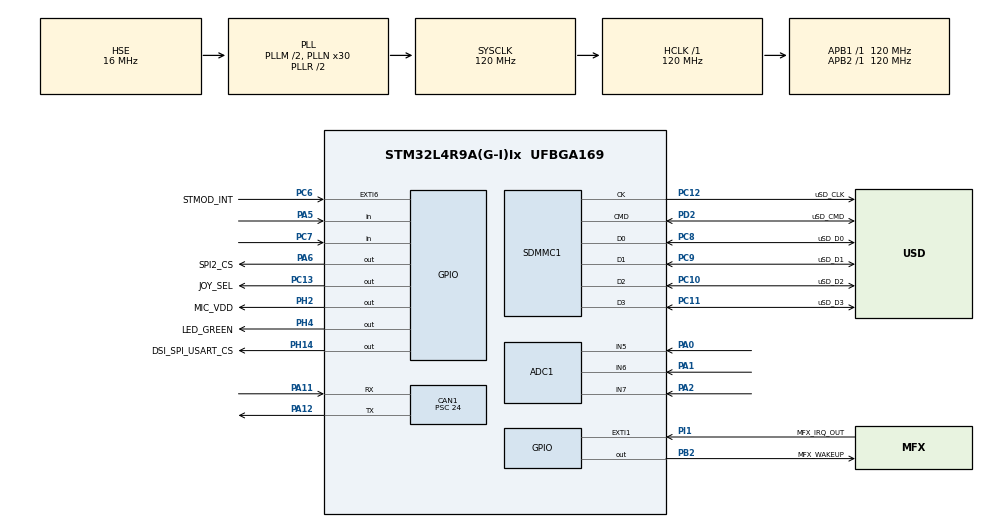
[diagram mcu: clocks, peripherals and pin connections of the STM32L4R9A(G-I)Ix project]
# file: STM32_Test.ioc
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ADC1.Channel-0\#ChannelRegularConversion=ADC_CHANNEL_5
ADC1.Channel-1\#ChannelRegularConversion=ADC_CHANNEL_6
ADC1.Channel-2\#ChannelRegularConversion=ADC_CHANNEL_7
ADC1.ClockPrescaler=ADC_CLOCK_ASYNC_DIV4
ADC1.ContinuousConvMode=ENABLE
ADC1.DMAContinuousRequests=ENABLE
ADC1.DataAlign=ADC_DATAALIGN_RIGHT
ADC1.EOCSelection=ADC_EOC_SEQ_CONV
ADC1.NbrOfConversion=3
ADC1.NbrOfConversionFlag=1
ADC1.OffsetNumber-0\#ChannelRegularConversion=ADC_OFFSET_NONE
ADC1.OffsetNumber-1\#ChannelRegularConversion=ADC_OFFSET_NONE
ADC1.OffsetNumber-2\#ChannelRegularConversion=ADC_OFFSET_NONE
ADC1.Rank-0\#ChannelRegularConversion=1
ADC1.Rank-1\#ChannelRegularConversion=2
ADC1.Rank-2\#ChannelRegularConversion=3
ADC1.SamplingTime-0\#ChannelRegularConversion=ADC_SAMPLETIME_92CYCLES_5
ADC1.SamplingTime-1\#ChannelRegularConversion=ADC_SAMPLETIME_92CYCLES_5
ADC1.SamplingTime-2\#ChannelRegularConversion=ADC_SAMPLETIME_92CYCLES_5
ADC1.master=1
CAN1.BS1=CAN_BS1_8TQ
CAN1.CalculateBaudRate=500000
CAN1.CalculateTimeBit=2000
CAN1.CalculateTimeQuantum=200.0
CAN1.Prescaler=24
DSIHOST_CKN.GPIO_Label=DSI_CK_N
DSIHOST_CKN.Signal=DSIHOST_CKN
DSIHOST_CKP.GPIO_Label=DSI_CK_P
DSIHOST_CKP.Signal=DSIHOST_CKP
DSIHOST_D0N.GPIO_Label=DSI_D0_N
DSIHOST_D0N.Signal=DSIHOST_D0N
DSIHOST_D0P.GPIO_Label=DSI_D0_P
DSIHOST_D0P.Signal=DSIHOST_D0P
DSIHOST_D1N.GPIO_Label=DSI_D1_N
DSIHOST_D1N.Signal=DSIHOST_D1N
DSIHOST_D1P.GPIO_Label=DSI_D1_P
DSIHOST_D1P.Signal=DSIHOST_D1P
Dma.ADC1.0.Direction=DMA_PERIPH_TO_MEMORY
Dma.ADC1.0.EventEnable=DISABLE
Dma.ADC1.0.Instance=DMA1_Channel4
Dma.ADC1.0.MemDataAlignment=DMA_MDATAALIGN_HALFWORD
Dma.ADC1.0.MemInc=DMA_MINC_ENABLE
Dma.ADC1.0.Mode=DMA_CIRCULAR
Dma.ADC1.0.PeriphDataAlignment=DMA_PDATAALIGN_HALFWORD
Dma.ADC1.0.PeriphInc=DMA_PINC_DISABLE
Dma.ADC1.0.Polarity=HAL_DMAMUX_REQUEST_GEN_RISING
Dma.ADC1.0.Priority=DMA_PRIORITY_VERY_HIGH
Dma.ADC1.0.RequestNumber=1
Dma.ADC1.0.SignalID=NONE
Dma.ADC1.0.SyncEnable=DISABLE
Dma.ADC1.0.SyncPolarity=HAL_DMAMUX_SYNC_NO_EVENT
Dma.ADC1.0.SyncRequestNumber=1
Dma.ADC1.0.SyncSignalID=NONE
Dma.Request0=ADC1
FATFS.BSP.number=1
FATFS._USE_MUTEX=1
FATFS0.BSP.STBoard=false
FATFS0.BSP.api=Unknown
FATFS0.BSP.instance=PC7
FATFS0.BSP.ip=GPIO
FATFS0.BSP.mode=Input
FATFS0.BSP.name=Detect_SDIO
FATFS0.BSP.solution=PC7
FREERTOS.Tasks01=defaultTask,24,128,StartDefaultTask,Default,NULL,Dynamic,NULL,NULL
FREERTOS.configUSE_NEWLIB_REENTRANT=1
Mcu.Family=STM32L4
Mcu.Name=STM32L4R9A(G-I)Ix
Mcu.Package=UFBGA169
NVIC.ADC1_IRQn=true\:5\:0\:false\:false\:true\:true\:true\:true\:true
NVIC.CAN1_RX0_IRQn=true\:5\:0\:false\:false\:true\:true\:true\:true\:true
NVIC.DMA1_Channel4_IRQn=true\:5\:0\:false\:false\:true\:true\:false\:true\:true
NVIC.PriorityGroup=NVIC_PRIORITYGROUP_4
NVIC.SDMMC1_IRQn=true\:5\:0\:false\:false\:true\:true\:true\:true\:true
NVIC.TIM6_DAC_IRQn=true\:15\:0\:false\:false\:true\:false\:false\:true\:true
NVIC.TimeBase=TIM6_DAC_IRQn
NVIC.TimeBaseIP=TIM6
PA0.Signal=ADCx_IN5
PA1.Signal=ADCx_IN6
PA10.GPIO_Label=USB_OTGFS_ID
PA10.Signal=USB_OTG_FS_ID
PA11.Mode=CAN_Activate
PA11.Signal=CAN1_RX
PA12.Mode=CAN_Activate
PA12.Signal=CAN1_TX
PA13\ (JTMS/SWDIO).GPIO_Label=SWDIO
PA13\ (JTMS/SWDIO).Mode=Serial_Wire
PA13\ (JTMS/SWDIO).Signal=SYS_JTMS-SWDIO
PA14\ (JTCK/SWCLK).GPIO_Label=SWCLK
PA14\ (JTCK/SWCLK).Mode=Serial_Wire
PA14\ (JTCK/SWCLK).Signal=SYS_JTCK-SWCLK
PA15\ (JTDI).GPIO_Label=USART3_RTS
PA15\ (JTDI).Signal=USART3_RTS
PA2.Signal=ADCx_IN7
PA3.GPIO_Label=USART2_RX
PA3.Signal=USART2_RX
PA4.GPIO_Label=DCMI_HSYNC
PA4.Signal=DCMI_HSYNC
PA5.GPIO_PuPd=GPIO_NOPULL
PA5.Signal=GPIO_Input
PA6.GPIO_Label=SPI2_CS
PA6.Signal=GPIO_Output
PA7.GPIO_Label=ARD_A0
PA7.Signal=ADCx_IN12
PB0.GPIO_Label=ARD_A3
PB0.Signal=ADCx_IN15
PB10.GPIO_Label=USART3_TX
PB10.Signal=USART3_TX
PB11.GPIO_Label=USART3_RX
PB11.Signal=USART3_RX
PB12.GPIO_Label=DFDATIN1
PB12.Signal=S_DATAIN1DFSDM1
PB13.GPIO_Label=SPI2_CLK
PB13.Signal=SPI2_SCK
PB14.GPIO_Label=SPI2_MISO
PB14.Signal=SPI2_MISO
PB15.GPIO_Label=SPI_MOSI
PB15.Signal=SPI2_MOSI
PB2.GPIO_Label=MFX_WAKEUP
PB2.Signal=GPIO_Output
PB3\ (JTDO/TRACESWO).GPIO_Label=SWO
PB3\ (JTDO/TRACESWO).Signal=SYS_JTDO-SWO
PB4\ (NJTRST).GPIO_Label=ARD_D6
PB4\ (NJTRST).Signal=S_TIM3_CH1
PB5.GPIO_Label=SAI1_SDB
PB5.Signal=SAI1_SD_B
PB6.GPIO_Label=I2C1_SCL
PB6.GPIO_Pu=GPIO_PULLUP
PB6.Signal=I2C1_SCL
PB7.GPIO_Label=PSRAM_ADV
PB7.Signal=FMC_NL
PB9.GPIO_Label=SAI1_FSA
PB9.Signal=SAI1_FS_A
PC0.GPIO_Label=ARD_D0
PC0.Signal=LPUART1_RX
PC1.GPIO_Label=ARD_D1
PC1.Signal=LPUART1_TX
PC10.GPIO_Label=uSD_D2
PC10.Mode=SD_4_bits_Wide_bus
PC10.Signal=SDMMC1_D2
PC11.GPIO_Label=uSD_D3
PC11.Mode=SD_4_bits_Wide_bus
PC11.Signal=SDMMC1_D3
PC12.GPIO_Label=uSD_CLK
PC12.Mode=SD_4_bits_Wide_bus
PC12.Signal=SDMMC1_CK
PC13.GPIO_Label=JOY_SEL
PC13.Signal=GPIO_Output
PC14-OSC32_IN\ (PC14).Mode=LSE-External-Oscillator
PC14-OSC32_IN\ (PC14).Signal=RCC_OSC32_IN
PC15-OSC32_OUT\ (PC15).Mode=LSE-External-Oscillator
PC15-OSC32_OUT\ (PC15).Signal=RCC_OSC32_OUT
PC2.GPIO_Label=DF_CKOUT
PC2.Signal=S_CKOUTDFSDM1
PC3.GPIO_Label=ARD_A2
PC3.Signal=ADCx_IN4
PC4.GPIO_Label=ARD_A1
PC4.Signal=ADCx_IN13
PC6.GPIO_Label=STMOD_INT
PC6.Signal=GPXTI6
PC7.GPIO_PuPd=GPIO_PULLDOWN
PC7.Signal=GPIO_Input
PC8.GPIO_Label=uSD_D0
PC8.Mode=SD_4_bits_Wide_bus
PC8.Signal=SDMMC1_D0
PC9.GPIO_Label=uSD_D1
PC9.Mode=SD_4_bits_Wide_bus
PC9.Signal=SDMMC1_D1
PD0.GPIO_Label=D2
PD0.Signal=FMC_D2_DA2
PD1.GPIO_Label=D3
PD1.Signal=FMC_D3_DA3
PD10.GPIO_Label=D15
PD10.Signal=FMC_D15_DA15
PD11.GPIO_Label=PSRAM_A16
PD11.Signal=FMC_A16_CLE
PD12.GPIO_Label=PSRAM_A17
PD12.Signal=FMC_A17_ALE
PD13.GPIO_Label=PSRAM_A18
PD13.Signal=FMC_A18
PD14.GPIO_Label=D0
PD14.Signal=FMC_D0_DA0
PD15.GPIO_Label=D1
PD15.Signal=FMC_D1_DA1
PD2.GPIO_Label=uSD_CMD
PD2.Mode=SD_4_bits_Wide_bus
PD2.Signal=SDMMC1_CMD
PD3.GPIO_Label=PSRAM_CLK
PD3.Signal=FMC_CLK
PD4.GPIO_Label=PSRAM_OE
PD4.Signal=FMC_NOE
PD5.GPIO_Label=PSRAM_WE
PD5.Signal=FMC_NWE
PD6.GPIO_Label=PSRAM_WAIT
PD6.Signal=FMC_NWAIT
PD7.GPIO_Label=PSRAM_NE1
PD7.Signal=FMC_NE1
PD8.GPIO_Label=D13
PD8.Signal=FMC_D13_DA13
PD9.GPIO_Label=D14
PD9.Signal=FMC_D14_DA14
PE0.GPIO_Label=PSRAM_NBL0
PE0.Signal=FMC_NBL0
PE1.GPIO_Label=PSRAM_NBL1
PE1.Signal=FMC_NBL1
PE10.GPIO_Label=D7
PE10.Signal=FMC_D7_DA7
PE11.GPIO_Label=D8
PE11.Signal=FMC_D8_DA8
PE12.GPIO_Label=D9
PE12.Signal=FMC_D9_DA9
PE13.GPIO_Label=D10
PE13.Signal=FMC_D10_DA10
PE14.GPIO_Label=D11
PE14.Signal=FMC_D11_DA11
PE15.GPIO_Label=D12
PE15.Signal=FMC_D12_DA12
PE2.GPIO_Label=SAI1_MCKA
PE2.Signal=SAI1_MCLK_A
PE3.GPIO_Label=PSRAM_A19
PE3.Signal=FMC_A19
PE4.GPIO_Label=PSRAM_A20
PE4.Signal=FMC_A20
PE5.GPIO_Label=SAI1_SCKA
PE5.Signal=SAI1_SCK_A
PE6.GPIO_Label=SAI1_SDA
PE6.Signal=SAI1_SD_A
PE7.GPIO_Label=D4
PE7.Signal=FMC_D4_DA4
PE8.GPIO_Label=D5
PE8.Signal=FMC_D5_DA5
PE9.GPIO_Label=D6
PE9.Signal=FMC_D6_DA6
PF0.GPIO_Label=PSRAM_A0
PF0.Signal=FMC_A0
PF1.GPIO_Label=PSRAM_A1
PF1.Signal=FMC_A1
PF11.GPIO_Label=DSI_TE
PF11.Signal=DSIHOST_TE
PF12.GPIO_Label=PSRAM_A6
PF12.Signal=FMC_A6
PF13.GPIO_Label=PSRAM_A7
PF13.Signal=FMC_A7
PF14.GPIO_Label=PSRAM_A8
PF14.Signal=FMC_A8
PF15.GPIO_Label=PSRAM_A9
PF15.Signal=FMC_A9
PF2.GPIO_Label=PSRAM_A2
PF2.Signal=FMC_A2
PF3.GPIO_Label=PSRAM_A3
PF3.Signal=FMC_A3
PF4.GPIO_Label=PSRAM_A4
PF4.Signal=FMC_A4
PF5.GPIO_Label=PSRAM_A5
PF5.Signal=FMC_A5
PG0.GPIO_Label=PSRAM_A10
PG0.Signal=FMC_A10
PG1.GPIO_Label=PSRAM_A11
PG1.Signal=FMC_A11
PG10.GPIO_Label=OCTOSPIM_P2_IO7
PG10.Signal=OCTOSPIM_P2_IO7
PG12.GPIO_Label=OCTOSPIM_P2_CS
PG12.Signal=OCTOSPIM_P2_NCS
PG13.GPIO_Label=I2C1_SDA
PG13.GPIO_Pu=GPIO_PULLUP
PG13.Signal=I2C1_SDA
PG15.GPIO_Label=OCTOSPIM_P2_DQS
PG15.Signal=OCTOSPIM_P2_DQS
PG2.GPIO_Label=PSRAM_A12
PG2.Signal=FMC_A12
PG3.GPIO_Label=PSRAM_A13
PG3.Signal=FMC_A13
PG4.GPIO_Label=PSRAM_A14
PG4.Signal=FMC_A14
PG5.GPIO_Label=PSRAM_A15
PG5.Signal=FMC_A15
PG7.GPIO_Label=ARD_15
PG7.Signal=I2C3_SCL
PG8.GPIO_Label=ARD_14
PG8.Signal=I2C3_SDA
PG9.GPIO_Label=OCTOSPIM_P2_IO6
PG9.Signal=OCTOSPIM_P2_IO6
PH0-OSC_IN\ (PH0).Mode=HSE-External-Clock-Source
PH0-OSC_IN\ (PH0).Signal=RCC_OSC_IN
PH1-OSC_OUT\ (PH1).Signal=RCC_OSC_OUT
PH10.GPIO_Label=OCTOSPIM_P2_IO5
PH10.Signal=OCTOSPIM_P2_IO5
PH11.GPIO_Label=DCMI_D2
PH11.Signal=DCMI_D2
PH12.GPIO_Label=DCMI_D3
PH12.Signal=DCMI_D3
PH13.GPIO_Label=ARD_D9
PH13.Signal=TIM8_CH1N
PH14.GPIO_Label=DSI_SPI_USART_CS
PH14.Signal=GPIO_Output
PH2.GPIO_Label=MIC_VDD
PH2.Signal=GPIO_Output
PH4.GPIO_Label=LED_GREEN
PH4.Signal=GPIO_Output
PH5.GPIO_Label=DCMI_PIXCLK
PH5.Signal=DCMI_PIXCLK
PH8.GPIO_Label=OCTOSPI_P2_IO3
PH8.Signal=OCTOSPIM_P2_IO3
PH9.GPIO_Label=OCTOPSIM_P2_IO4
PH9.Signal=OCTOSPIM_P2_IO4
PI0.GPIO_Label=ARD_10
PI0.Signal=SPI2_NSS
PI1.GPIO_Label=MFX_IRQ_OUT
PI1.Signal=GPXTI1
PI10.GPIO_Label=OCTOSPIM_P2_IO1
PI10.Signal=OCTOSPIM_P2_IO1
PI11.GPIO_Label=OCTOSPIM_P2_IO0
PI11.Signal=OCTOSPIM_P2_IO0
PI4.GPIO_Label=DCMI_D5
PI4.Signal=DCMI_D5
PI5.GPIO_Label=DCMI_VSYNC
PI5.Signal=DCMI_VSYNC
PI6.GPIO_Label=OCTOSPIM_P2_CLK
PI6.Signal=OCTOSPIM_P2_CLK
PI7.GPIO_Label=DCMI_D7
PI7.Signal=DCMI_D7
ProjectManager.HeapSize=0x400
ProjectManager.StackSize=0x800
ProjectManager.TargetToolchain=STM32CubeIDE
RCC.ADCFreq_Value=32000000
RCC.AHBFreq_Value=120000000
RCC.APB1Freq_Value=120000000
RCC.APB1TimFreq_Value=120000000
RCC.APB2Freq_Value=120000000
RCC.APB2TimFreq_Value=120000000
RCC.CortexFreq_Value=120000000
RCC.HCLKFreq_Value=120000000
RCC.HSE_VALUE=16000000
RCC.HSI48_VALUE=48000000
RCC.HSI_VALUE=16000000
RCC.MSI_VALUE=4000000
RCC.PLLDSINDIV=32
RCC.PLLM1=2
RCC.PLLM2=2
RCC.PLLN=30
RCC.PLLSourceVirtual=RCC_PLLSOURCE_HSE
RCC.SYSCLKFreq_VALUE=120000000
RCC.SYSCLKSource=RCC_SYSCLKSOURCE_PLLCLK
RCC.USBFreq_Value=32000000
RCC.VCOOutputFreq_Value=240000000
SH.ADCx_IN12.0=ADC1_IN12
SH.ADCx_IN13.0=ADC1_IN13
SH.ADCx_IN15.0=ADC1_IN15
SH.ADCx_IN4.0=ADC1_IN4
SH.ADCx_IN5.0=ADC1_IN5,IN5-Single-Ended
SH.ADCx_IN6.0=ADC1_IN6,IN6-Single-Ended
SH.ADCx_IN7.0=ADC1_IN7,IN7-Single-Ended
SH.FMC_A0.0=FMC_A0
SH.FMC_A1.0=FMC_A1
SH.FMC_A10.0=FMC_A10
SH.FMC_A11.0=FMC_A11
SH.FMC_A12.0=FMC_A12
SH.FMC_A13.0=FMC_A13
SH.FMC_A14.0=FMC_A14
SH.FMC_A15.0=FMC_A15
SH.FMC_A16_CLE.0=FMC_A16
SH.FMC_A17_ALE.0=FMC_A17
SH.FMC_A18.0=FMC_A18
SH.FMC_A19.0=FMC_A19
SH.FMC_A2.0=FMC_A2
SH.FMC_A20.0=FMC_A20
SH.FMC_A3.0=FMC_A3
SH.FMC_A4.0=FMC_A4
SH.FMC_A5.0=FMC_A5
SH.FMC_A6.0=FMC_A6
SH.FMC_A7.0=FMC_A7
SH.FMC_A8.0=FMC_A8
SH.FMC_A9.0=FMC_A9
SH.FMC_CLK.0=FMC_CLK
SH.FMC_D0_DA0.0=FMC_D0
SH.FMC_D10_DA10.0=FMC_D10
SH.FMC_D11_DA11.0=FMC_D11
SH.FMC_D12_DA12.0=FMC_D12
SH.FMC_D13_DA13.0=FMC_D13
SH.FMC_D14_DA14.0=FMC_D14
SH.FMC_D15_DA15.0=FMC_D15
SH.FMC_D1_DA1.0=FMC_D1
SH.FMC_D2_DA2.0=FMC_D2
SH.FMC_D3_DA3.0=FMC_D3
SH.FMC_D4_DA4.0=FMC_D4
SH.FMC_D5_DA5.0=FMC_D5
SH.FMC_D6_DA6.0=FMC_D6
SH.FMC_D7_DA7.0=FMC_D7
SH.FMC_D8_DA8.0=FMC_D8
SH.FMC_D9_DA9.0=FMC_D9
SH.FMC_NBL0.0=FMC_NBL0
SH.FMC_NBL1.0=FMC_NBL1
SH.FMC_NL.0=FMC_NL
SH.FMC_NOE.0=FMC_NOE
SH.FMC_NWAIT.0=FMC_NWAIT
SH.FMC_NWE.0=FMC_NWE
SH.S_CKOUTDFSDM1.0=DFSDM1_CKOUT
SH.S_DATAIN1DFSDM1.0=DFSDM1_DATIN1
SH.S_TIM3_CH1.0=TIM3_CH1
VP_FATFS_VS_SDIO.Mode=SDIO
VP_FREERTOS_VS_CMSIS_V2.Mode=CMSIS_V2
VP_SYS_VS_tim6.Mode=TIM6
board=STM32L4R9I-DISCO

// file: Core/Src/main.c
/* USER CODE BEGIN Header */
/**
  ******************************************************************************
  * @file           : main.c
  * @brief          : Main program body
  ******************************************************************************
  * @attention
  *
  * Copyright (c) 2023 STMicroelectronics.
  * All rights reserved.
  *
  * This software is licensed under terms that can be found in the LICENSE file
  * in the root directory of this software component.
  * If no LICENSE file comes with this software, it is provided AS-IS.
  *
  ******************************************************************************
  */
/* USER CODE END Header */
#include "main.h"
#include "cmsis_os.h"
#include "fatfs.h"

/* USER CODE BEGIN Includes */
#include "adc_task.h"
#include "sd_task.h"
#include "controller_task.h"
#include "can_task.h"
/* USER CODE END Includes */

/* USER CODE BEGIN PM */
///user defined variables///

/* USER CODE END PM */

ADC_HandleTypeDef hadc1;
DMA_HandleTypeDef hdma_adc1;

CAN_HandleTypeDef hcan1;

SD_HandleTypeDef hsd1;

/* Definitions for defaultTask */
osThreadId_t defaultTaskHandle;
const osThreadAttr_t defaultTask_attributes = {
  .name = "defaultTask",
  .stack_size = 128 * 4,
  .priority = (osPriority_t) osPriorityNormal,
};
/* USER CODE BEGIN PV */

/* Definitions for myMutex01 */
/* Definitions for threads */

//osThreadId_t thr_2;
//const osThreadAttr_t thr_2_attributes = {
//  .name = "defaultTask",
//  .stack_size = 128 * 4,
//  .priority = (osPriority_t) osPriorityNormal,
//};
/* USER CODE END PV */

void SystemClock_Config(void);
static void MX_GPIO_Init(void);
static void MX_DMA_Init(void);
static void MX_SDMMC1_SD_Init(void);
static void MX_CAN1_Init(void);
static void MX_ADC1_Init(void);
void StartDefaultTask(void *argument);

int main(void)
{

  /* MCU Configuration--------------------------------------------------------*/

  /* Reset of all peripherals, Initializes the Flash interface and the Systick. */
  HAL_Init();

  /* Configure the system clock */
  SystemClock_Config();

  /* Initialize all configured peripherals */
  MX_GPIO_Init();
  MX_DMA_Init();
  MX_SDMMC1_SD_Init();
  MX_CAN1_Init();
  MX_ADC1_Init();
  MX_FATFS_Init();

  /* Init scheduler */
  osKernelInitialize();

  /* Create the thread(s) */
  /* creation of defaultTask */
  defaultTaskHandle = osThreadNew(StartDefaultTask, NULL, &defaultTask_attributes);

  /* USER CODE BEGIN RTOS_THREADS */
  /* Initialize user threads ... */
  ADC_Init(&hadc1);
  can_Init();
  state_machine_init();
  /* USER CODE END RTOS_THREADS */

  /* Start scheduler */
  osKernelStart();

  /* We should never get here as control is now taken by the scheduler */
  /* Infinite loop */
  while (1)
  {

  }
}

void SystemClock_Config(void)
{
  RCC_OscInitTypeDef RCC_OscInitStruct = {0};
  RCC_ClkInitTypeDef RCC_ClkInitStruct = {0};

  /** Configure the main internal regulator output voltage
  */
  if (HAL_PWREx_ControlVoltageScaling(PWR_REGULATOR_VOLTAGE_SCALE1_BOOST) != HAL_OK)
  {
    Error_Handler();
  }

  /** Initializes the RCC Oscillators according to the specified parameters
  * in the RCC_OscInitTypeDef structure.
  */
  RCC_OscInitStruct.OscillatorType = RCC_OSCILLATORTYPE_HSE;
  RCC_OscInitStruct.HSEState = RCC_HSE_BYPASS;
  RCC_OscInitStruct.PLL.PLLState = RCC_PLL_ON;
  RCC_OscInitStruct.PLL.PLLSource = RCC_PLLSOURCE_HSE;
  RCC_OscInitStruct.PLL.PLLM = 2;
  RCC_OscInitStruct.PLL.PLLN = 30;
  RCC_OscInitStruct.PLL.PLLP = RCC_PLLP_DIV2;
  RCC_OscInitStruct.PLL.PLLQ = RCC_PLLQ_DIV2;
  RCC_OscInitStruct.PLL.PLLR = RCC_PLLR_DIV2;
  if (HAL_RCC_OscConfig(&RCC_OscInitStruct) != HAL_OK)
  {
    Error_Handler();
  }

  /** Initializes the CPU, AHB and APB buses clocks
  */
  RCC_ClkInitStruct.ClockType = RCC_CLOCKTYPE_HCLK|RCC_CLOCKTYPE_SYSCLK
                              |RCC_CLOCKTYPE_PCLK1|RCC_CLOCKTYPE_PCLK2;
  RCC_ClkInitStruct.SYSCLKSource = RCC_SYSCLKSOURCE_PLLCLK;
  RCC_ClkInitStruct.AHBCLKDivider = RCC_SYSCLK_DIV1;
  RCC_ClkInitStruct.APB1CLKDivider = RCC_HCLK_DIV1;
  RCC_ClkInitStruct.APB2CLKDivider = RCC_HCLK_DIV1;

  if (HAL_RCC_ClockConfig(&RCC_ClkInitStruct, FLASH_LATENCY_5) != HAL_OK)
  {
    Error_Handler();
  }
}

static void MX_ADC1_Init(void)
{

  ADC_ChannelConfTypeDef sConfig = {0};

  /** Common config
  */
  hadc1.Instance = ADC1;
  hadc1.Init.ClockPrescaler = ADC_CLOCK_ASYNC_DIV4;
  hadc1.Init.Resolution = ADC_RESOLUTION_12B;
  hadc1.Init.DataAlign = ADC_DATAALIGN_RIGHT;
  hadc1.Init.ScanConvMode = ADC_SCAN_ENABLE;
  hadc1.Init.EOCSelection = ADC_EOC_SEQ_CONV;
  hadc1.Init.LowPowerAutoWait = DISABLE;
  hadc1.Init.ContinuousConvMode = ENABLE;
  hadc1.Init.NbrOfConversion = 3;
  hadc1.Init.DiscontinuousConvMode = DISABLE;
  hadc1.Init.ExternalTrigConv = ADC_SOFTWARE_START;
  hadc1.Init.ExternalTrigConvEdge = ADC_EXTERNALTRIGCONVEDGE_NONE;
  hadc1.Init.DMAContinuousRequests = ENABLE;
  hadc1.Init.Overrun = ADC_OVR_DATA_PRESERVED;
  hadc1.Init.OversamplingMode = DISABLE;
  hadc1.Init.DFSDMConfig = ADC_DFSDM_MODE_ENABLE;
  if (HAL_ADC_Init(&hadc1) != HAL_OK)
  {
    Error_Handler();
  }

  /** Configure Regular Channel
  */
  sConfig.Channel = ADC_CHANNEL_5;
  sConfig.Rank = ADC_REGULAR_RANK_1;
  sConfig.SamplingTime = ADC_SAMPLETIME_92CYCLES_5;
  sConfig.SingleDiff = ADC_SINGLE_ENDED;
  sConfig.OffsetNumber = ADC_OFFSET_NONE;
  sConfig.Offset = 0;
  if (HAL_ADC_ConfigChannel(&hadc1, &sConfig) != HAL_OK)
  {
    Error_Handler();
  }

  /** Configure Regular Channel
  */
  sConfig.Channel = ADC_CHANNEL_6;
  sConfig.Rank = ADC_REGULAR_RANK_2;
  if (HAL_ADC_ConfigChannel(&hadc1, &sConfig) != HAL_OK)
  {
    Error_Handler();
  }

  /** Configure Regular Channel
  */
  sConfig.Channel = ADC_CHANNEL_7;
  sConfig.Rank = ADC_REGULAR_RANK_3;
  if (HAL_ADC_ConfigChannel(&hadc1, &sConfig) != HAL_OK)
  {
    Error_Handler();
  }

}

static void MX_CAN1_Init(void)
{

  hcan1.Instance = CAN1;
  hcan1.Init.Prescaler = 24;
  hcan1.Init.Mode = CAN_MODE_NORMAL;
  hcan1.Init.SyncJumpWidth = CAN_SJW_1TQ;
  hcan1.Init.TimeSeg1 = CAN_BS1_8TQ;
  hcan1.Init.TimeSeg2 = CAN_BS2_1TQ;
  hcan1.Init.TimeTriggeredMode = DISABLE;
  hcan1.Init.AutoBusOff = DISABLE;
  hcan1.Init.AutoWakeUp = DISABLE;
  hcan1.Init.AutoRetransmission = DISABLE;
  hcan1.Init.ReceiveFifoLocked = DISABLE;
  hcan1.Init.TransmitFifoPriority = DISABLE;
  if (HAL_CAN_Init(&hcan1) != HAL_OK)
  {
    Error_Handler();
  }

}

static void MX_SDMMC1_SD_Init(void)
{

  hsd1.Instance = SDMMC1;
  hsd1.Init.ClockEdge = SDMMC_CLOCK_EDGE_RISING;
  hsd1.Init.ClockPowerSave = SDMMC_CLOCK_POWER_SAVE_DISABLE;
  hsd1.Init.BusWide = SDMMC_BUS_WIDE_4B;
  hsd1.Init.HardwareFlowControl = SDMMC_HARDWARE_FLOW_CONTROL_DISABLE;
  hsd1.Init.ClockDiv = 0;
  hsd1.Init.Transceiver = SDMMC_TRANSCEIVER_DISABLE;

}

static void MX_DMA_Init(void)
{

  /* DMA controller clock enable */
  __HAL_RCC_DMAMUX1_CLK_ENABLE();
  __HAL_RCC_DMA1_CLK_ENABLE();

  /* DMA interrupt init */
  /* DMA1_Channel4_IRQn interrupt configuration */
  HAL_NVIC_SetPriority(DMA1_Channel4_IRQn, 5, 0);
  HAL_NVIC_EnableIRQ(DMA1_Channel4_IRQn);

}

static void MX_GPIO_Init(void)
{
  GPIO_InitTypeDef GPIO_InitStruct = {0};

  /* GPIO Ports Clock Enable */
  __HAL_RCC_GPIOI_CLK_ENABLE();
  __HAL_RCC_GPIOH_CLK_ENABLE();
  __HAL_RCC_GPIOE_CLK_ENABLE();
  __HAL_RCC_GPIOB_CLK_ENABLE();
  __HAL_RCC_GPIOA_CLK_ENABLE();
  __HAL_RCC_GPIOG_CLK_ENABLE();
  HAL_PWREx_EnableVddIO2();
  __HAL_RCC_GPIOD_CLK_ENABLE();
  __HAL_RCC_GPIOC_CLK_ENABLE();
  __HAL_RCC_GPIOF_CLK_ENABLE();

  /*Configure GPIO pin Output Level */
  HAL_GPIO_WritePin(GPIOH, MIC_VDD_Pin|DSI_SPI_USART_CS_Pin|LED_GREEN_Pin, GPIO_PIN_RESET);

  /*Configure GPIO pin Output Level */
  HAL_GPIO_WritePin(JOY_SEL_GPIO_Port, JOY_SEL_Pin, GPIO_PIN_RESET);

  /*Configure GPIO pin Output Level */
  HAL_GPIO_WritePin(SPI2_CS_GPIO_Port, SPI2_CS_Pin, GPIO_PIN_RESET);

  /*Configure GPIO pin Output Level */
  HAL_GPIO_WritePin(MFX_WAKEUP_GPIO_Port, MFX_WAKEUP_Pin, GPIO_PIN_RESET);

  /*Configure GPIO pins : OCTOSPIM_P2_IO1_Pin OCTOSPIM_P2_CLK_Pin OCTOSPIM_P2_IO0_Pin */
  GPIO_InitStruct.Pin = OCTOSPIM_P2_IO1_Pin|OCTOSPIM_P2_CLK_Pin|OCTOSPIM_P2_IO0_Pin;
  GPIO_InitStruct.Mode = GPIO_MODE_AF_PP;
  GPIO_InitStruct.Pull = GPIO_NOPULL;
  GPIO_InitStruct.Speed = GPIO_SPEED_FREQ_VERY_HIGH;
  GPIO_InitStruct.Alternate = GPIO_AF5_OCTOSPIM_P2;
  HAL_GPIO_Init(GPIOI, &GPIO_InitStruct);

  /*Configure GPIO pins : MIC_VDD_Pin DSI_SPI_USART_CS_Pin LED_GREEN_Pin */
  GPIO_InitStruct.Pin = MIC_VDD_Pin|DSI_SPI_USART_CS_Pin|LED_GREEN_Pin;
  GPIO_InitStruct.Mode = GPIO_MODE_OUTPUT_PP;
  GPIO_InitStruct.Pull = GPIO_NOPULL;
  GPIO_InitStruct.Speed = GPIO_SPEED_FREQ_LOW;
  HAL_GPIO_Init(GPIOH, &GPIO_InitStruct);

  /*Configure GPIO pins : PSRAM_NBL0_Pin PSRAM_NBL1_Pin PSRAM_A20_Pin PSRAM_A19_Pin
                           D7_Pin D6_Pin D12_Pin D5_Pin
                           D11_Pin D4_Pin D10_Pin D9_Pin
                           D8_Pin */
  GPIO_InitStruct.Pin = PSRAM_NBL0_Pin|PSRAM_NBL1_Pin|PSRAM_A20_Pin|PSRAM_A19_Pin
                          |D7_Pin|D6_Pin|D12_Pin|D5_Pin
                          |D11_Pin|D4_Pin|D10_Pin|D9_Pin
                          |D8_Pin;
  GPIO_InitStruct.Mode = GPIO_MODE_AF_PP;
  GPIO_InitStruct.Pull = GPIO_NOPULL;
  GPIO_InitStruct.Speed = GPIO_SPEED_FREQ_VERY_HIGH;
  GPIO_InitStruct.Alternate = GPIO_AF12_FMC;
  HAL_GPIO_Init(GPIOE, &GPIO_InitStruct);

  /*Configure GPIO pin : ARD_D6_Pin */
  GPIO_InitStruct.Pin = ARD_D6_Pin;
  GPIO_InitStruct.Mode = GPIO_MODE_AF_PP;
  GPIO_InitStruct.Pull = GPIO_NOPULL;
  GPIO_InitStruct.Speed = GPIO_SPEED_FREQ_LOW;
  GPIO_InitStruct.Alternate = GPIO_AF2_TIM3;
  HAL_GPIO_Init(ARD_D6_GPIO_Port, &GPIO_InitStruct);

  /*Configure GPIO pin : USART3_RTS_Pin */
  GPIO_InitStruct.Pin = USART3_RTS_Pin;
  GPIO_InitStruct.Mode = GPIO_MODE_AF_PP;
  GPIO_InitStruct.Pull = GPIO_NOPULL;
  GPIO_InitStruct.Speed = GPIO_SPEED_FREQ_VERY_HIGH;
  GPIO_InitStruct.Alternate = GPIO_AF7_USART3;
  HAL_GPIO_Init(USART3_RTS_GPIO_Port, &GPIO_InitStruct);

  /*Configure GPIO pin : ARD_10_Pin */
  GPIO_InitStruct.Pin = ARD_10_Pin;
  GPIO_InitStruct.Mode = GPIO_MODE_AF_PP;
  GPIO_InitStruct.Pull = GPIO_NOPULL;
  GPIO_InitStruct.Speed = GPIO_SPEED_FREQ_VERY_HIGH;
  GPIO_InitStruct.Alternate = GPIO_AF5_SPI2;
  HAL_GPIO_Init(ARD_10_GPIO_Port, &GPIO_InitStruct);

  /*Configure GPIO pins : DCMI_D7_Pin DCMI_D5_Pin DCMI_VSYNC_Pin */
  GPIO_InitStruct.Pin = DCMI_D7_Pin|DCMI_D5_Pin|DCMI_VSYNC_Pin;
  GPIO_InitStruct.Mode = GPIO_MODE_AF_PP;
  GPIO_InitStruct.Pull = GPIO_NOPULL;
  GPIO_InitStruct.Speed = GPIO_SPEED_FREQ_LOW;
  GPIO_InitStruct.Alternate = GPIO_AF10_DCMI;
  HAL_GPIO_Init(GPIOI, &GPIO_InitStruct);

  /*Configure GPIO pins : SAI1_SDB_Pin SAI1_FSA_Pin */
  GPIO_InitStruct.Pin = SAI1_SDB_Pin|SAI1_FSA_Pin;
  GPIO_InitStruct.Mode = GPIO_MODE_AF_PP;
  GPIO_InitStruct.Pull = GPIO_NOPULL;
  GPIO_InitStruct.Speed = GPIO_SPEED_FREQ_LOW;
  GPIO_InitStruct.Alternate = GPIO_AF13_SAI1;
  HAL_GPIO_Init(GPIOB, &GPIO_InitStruct);

  /*Configure GPIO pins : OCTOSPIM_P2_IO6_Pin OCTOSPIM_P2_DQS_Pin OCTOSPIM_P2_IO7_Pin OCTOSPIM_P2_CS_Pin */
  GPIO_InitStruct.Pin = OCTOSPIM_P2_IO6_Pin|OCTOSPIM_P2_DQS_Pin|OCTOSPIM_P2_IO7_Pin|OCTOSPIM_P2_CS_Pin;
  GPIO_InitStruct.Mode = GPIO_MODE_AF_PP;
  GPIO_InitStruct.Pull = GPIO_NOPULL;
  GPIO_InitStruct.Speed = GPIO_SPEED_FREQ_VERY_HIGH;
  GPIO_InitStruct.Alternate = GPIO_AF5_OCTOSPIM_P2;
  HAL_GPIO_Init(GPIOG, &GPIO_InitStruct);

  /*Configure GPIO pins : D2_Pin PSRAM_OE_Pin D3_Pin PSRAM_WE_Pin
                           PSRAM_WAIT_Pin PSRAM_CLK_Pin PSRAM_NE1_Pin PSRAM_A18_Pin
                           D1_Pin D0_Pin PSRAM_A17_Pin PSRAM_A16_Pin
                           D15_Pin D14_Pin D13_Pin */
  GPIO_InitStruct.Pin = D2_Pin|PSRAM_OE_Pin|D3_Pin|PSRAM_WE_Pin
                          |PSRAM_WAIT_Pin|PSRAM_CLK_Pin|PSRAM_NE1_Pin|PSRAM_A18_Pin
                          |D1_Pin|D0_Pin|PSRAM_A17_Pin|PSRAM_A16_Pin
                          |D15_Pin|D14_Pin|D13_Pin;
  GPIO_InitStruct.Mode = GPIO_MODE_AF_PP;
  GPIO_InitStruct.Pull = GPIO_NOPULL;
  GPIO_InitStruct.Speed = GPIO_SPEED_FREQ_VERY_HIGH;
  GPIO_InitStruct.Alternate = GPIO_AF12_FMC;
  HAL_GPIO_Init(GPIOD, &GPIO_InitStruct);

  /*Configure GPIO pin : MFX_IRQ_OUT_Pin */
  GPIO_InitStruct.Pin = MFX_IRQ_OUT_Pin;
  GPIO_InitStruct.Mode = GPIO_MODE_IT_RISING;
  GPIO_InitStruct.Pull = GPIO_NOPULL;
  HAL_GPIO_Init(MFX_IRQ_OUT_GPIO_Port, &GPIO_InitStruct);

  /*Configure GPIO pins : DCMI_D3_Pin DCMI_PIXCLK_Pin DCMI_D2_Pin */
  GPIO_InitStruct.Pin = DCMI_D3_Pin|DCMI_PIXCLK_Pin|DCMI_D2_Pin;
  GPIO_InitStruct.Mode = GPIO_MODE_AF_PP;
  GPIO_InitStruct.Pull = GPIO_NOPULL;
  GPIO_InitStruct.Speed = GPIO_SPEED_FREQ_LOW;
  GPIO_InitStruct.Alternate = GPIO_AF10_DCMI;
  HAL_GPIO_Init(GPIOH, &GPIO_InitStruct);

  /*Configure GPIO pin : I2C1_SCL_Pin */
  GPIO_InitStruct.Pin = I2C1_SCL_Pin;
  GPIO_InitStruct.Mode = GPIO_MODE_AF_OD;
  GPIO_InitStruct.Pull = GPIO_PULLUP;
  GPIO_InitStruct.Speed = GPIO_SPEED_FREQ_VERY_HIGH;
  GPIO_InitStruct.Alternate = GPIO_AF4_I2C1;
  HAL_GPIO_Init(I2C1_SCL_GPIO_Port, &GPIO_InitStruct);

  /*Configure GPIO pin : ARD_D9_Pin */
  GPIO_InitStruct.Pin = ARD_D9_Pin;
  GPIO_InitStruct.Mode = GPIO_MODE_AF_PP;
  GPIO_InitStruct.Pull = GPIO_NOPULL;
  GPIO_InitStruct.Speed = GPIO_SPEED_FREQ_LOW;
  GPIO_InitStruct.Alternate = GPIO_AF3_TIM8;
  HAL_GPIO_Init(ARD_D9_GPIO_Port, &GPIO_InitStruct);

  /*Configure GPIO pins : OCTOPSIM_P2_IO4_Pin OCTOSPIM_P2_IO5_Pin OCTOSPI_P2_IO3_Pin */
  GPIO_InitStruct.Pin = OCTOPSIM_P2_IO4_Pin|OCTOSPIM_P2_IO5_Pin|OCTOSPI_P2_IO3_Pin;
  GPIO_InitStruct.Mode = GPIO_MODE_AF_PP;
  GPIO_InitStruct.Pull = GPIO_NOPULL;
  GPIO_InitStruct.Speed = GPIO_SPEED_FREQ_VERY_HIGH;
  GPIO_InitStruct.Alternate = GPIO_AF5_OCTOSPIM_P2;
  HAL_GPIO_Init(GPIOH, &GPIO_InitStruct);

  /*Configure GPIO pins : SAI1_MCKA_Pin SAI1_SDA_Pin SAI1_SCKA_Pin */
  GPIO_InitStruct.Pin = SAI1_MCKA_Pin|SAI1_SDA_Pin|SAI1_SCKA_Pin;
  GPIO_InitStruct.Mode = GPIO_MODE_AF_PP;
  GPIO_InitStruct.Pull = GPIO_NOPULL;
  GPIO_InitStruct.Speed = GPIO_SPEED_FREQ_LOW;
  GPIO_InitStruct.Alternate = GPIO_AF13_SAI1;
  HAL_GPIO_Init(GPIOE, &GPIO_InitStruct);

  /*Configure GPIO pin : PSRAM_ADV_Pin */
  GPIO_InitStruct.Pin = PSRAM_ADV_Pin;
  GPIO_InitStruct.Mode = GPIO_MODE_AF_PP;
  GPIO_InitStruct.Pull = GPIO_NOPULL;
  GPIO_InitStruct.Speed = GPIO_SPEED_FREQ_VERY_HIGH;
  GPIO_InitStruct.Alternate = GPIO_AF12_FMC;
  HAL_GPIO_Init(PSRAM_ADV_GPIO_Port, &GPIO_InitStruct);

  /*Configure GPIO pin : USB_OTGFS_ID_Pin */
  GPIO_InitStruct.Pin = USB_OTGFS_ID_Pin;
  GPIO_InitStruct.Mode = GPIO_MODE_AF_PP;
  GPIO_InitStruct.Pull = GPIO_NOPULL;
  GPIO_InitStruct.Speed = GPIO_SPEED_FREQ_VERY_HIGH;
  GPIO_InitStruct.Alternate = GPIO_AF10_OTG_FS;
  HAL_GPIO_Init(USB_OTGFS_ID_GPIO_Port, &GPIO_InitStruct);

  /*Configure GPIO pin : JOY_SEL_Pin */
  GPIO_InitStruct.Pin = JOY_SEL_Pin;
  GPIO_InitStruct.Mode = GPIO_MODE_OUTPUT_PP;
  GPIO_InitStruct.Pull = GPIO_NOPULL;
  GPIO_InitStruct.Speed = GPIO_SPEED_FREQ_LOW;
  HAL_GPIO_Init(JOY_SEL_GPIO_Port, &GPIO_InitStruct);

  /*Configure GPIO pins : PSRAM_A2_Pin PSRAM_A1_Pin PSRAM_A0_Pin PSRAM_A3_Pin
                           PSRAM_A4_Pin PSRAM_A5_Pin PSRAM_A9_Pin PSRAM_A8_Pin
                           PSRAM_A7_Pin PSRAM_A6_Pin */
  GPIO_InitStruct.Pin = PSRAM_A2_Pin|PSRAM_A1_Pin|PSRAM_A0_Pin|PSRAM_A3_Pin
                          |PSRAM_A4_Pin|PSRAM_A5_Pin|PSRAM_A9_Pin|PSRAM_A8_Pin
                          |PSRAM_A7_Pin|PSRAM_A6_Pin;
  GPIO_InitStruct.Mode = GPIO_MODE_AF_PP;
  GPIO_InitStruct.Pull = GPIO_NOPULL;
  GPIO_InitStruct.Speed = GPIO_SPEED_FREQ_VERY_HIGH;
  GPIO_InitStruct.Alternate = GPIO_AF12_FMC;
  HAL_GPIO_Init(GPIOF, &GPIO_InitStruct);

  /*Configure GPIO pins : ARD_14_Pin ARD_15_Pin */
  GPIO_InitStruct.Pin = ARD_14_Pin|ARD_15_Pin;
  GPIO_InitStruct.Mode = GPIO_MODE_AF_OD;
  GPIO_InitStruct.Pull = GPIO_NOPULL;
  GPIO_InitStruct.Speed = GPIO_SPEED_FREQ_VERY_HIGH;
  GPIO_InitStruct.Alternate = GPIO_AF4_I2C3;
  HAL_GPIO_Init(GPIOG, &GPIO_InitStruct);

  /*Configure GPIO pin : STMOD_INT_Pin */
  GPIO_InitStruct.Pin = STMOD_INT_Pin;
  GPIO_InitStruct.Mode = GPIO_MODE_IT_RISING;
  GPIO_InitStruct.Pull = GPIO_NOPULL;
  HAL_GPIO_Init(STMOD_INT_GPIO_Port, &GPIO_InitStruct);

  /*Configure GPIO pin : I2C1_SDA_Pin */
  GPIO_InitStruct.Pin = I2C1_SDA_Pin;
  GPIO_InitStruct.Mode = GPIO_MODE_AF_OD;
  GPIO_InitStruct.Pull = GPIO_PULLUP;
  GPIO_InitStruct.Speed = GPIO_SPEED_FREQ_VERY_HIGH;
  GPIO_InitStruct.Alternate = GPIO_AF4_I2C1;
  HAL_GPIO_Init(I2C1_SDA_GPIO_Port, &GPIO_InitStruct);

  /*Configure GPIO pins : PSRAM_A14_Pin PSRAM_A13_Pin PSRAM_A15_Pin PSRAM_A11_Pin
                           PSRAM_A12_Pin PSRAM_A10_Pin */
  GPIO_InitStruct.Pin = PSRAM_A14_Pin|PSRAM_A13_Pin|PSRAM_A15_Pin|PSRAM_A11_Pin
                          |PSRAM_A12_Pin|PSRAM_A10_Pin;
  GPIO_InitStruct.Mode = GPIO_MODE_AF_PP;
  GPIO_InitStruct.Pull = GPIO_NOPULL;
  GPIO_InitStruct.Speed = GPIO_SPEED_FREQ_VERY_HIGH;
  GPIO_InitStruct.Alternate = GPIO_AF12_FMC;
  HAL_GPIO_Init(GPIOG, &GPIO_InitStruct);

  /*Configure GPIO pin : PC7 */
  GPIO_InitStruct.Pin = GPIO_PIN_7;
  GPIO_InitStruct.Mode = GPIO_MODE_INPUT;
  GPIO_InitStruct.Pull = GPIO_PULLDOWN;
  HAL_GPIO_Init(GPIOC, &GPIO_InitStruct);

  /*Configure GPIO pins : USART3_RX_Pin USART3_TX_Pin */
  GPIO_InitStruct.Pin = USART3_RX_Pin|USART3_TX_Pin;
  GPIO_InitStruct.Mode = GPIO_MODE_AF_PP;
  GPIO_InitStruct.Pull = GPIO_NOPULL;
  GPIO_InitStruct.Speed = GPIO_SPEED_FREQ_VERY_HIGH;
  GPIO_InitStruct.Alternate = GPIO_AF7_USART3;
  HAL_GPIO_Init(GPIOB, &GPIO_InitStruct);

  /*Configure GPIO pins : ARD_D0_Pin ARD_D1_Pin */
  GPIO_InitStruct.Pin = ARD_D0_Pin|ARD_D1_Pin;
  GPIO_InitStruct.Mode = GPIO_MODE_AF_PP;
  GPIO_InitStruct.Pull = GPIO_NOPULL;
  GPIO_InitStruct.Speed = GPIO_SPEED_FREQ_VERY_HIGH;
  GPIO_InitStruct.Alternate = GPIO_AF8_LPUART1;
  HAL_GPIO_Init(GPIOC, &GPIO_InitStruct);

  /*Configure GPIO pin : DF_CKOUT_Pin */
  GPIO_InitStruct.Pin = DF_CKOUT_Pin;
  GPIO_InitStruct.Mode = GPIO_MODE_AF_PP;
  GPIO_InitStruct.Pull = GPIO_NOPULL;
  GPIO_InitStruct.Speed = GPIO_SPEED_FREQ_LOW;
  GPIO_InitStruct.Alternate = GPIO_AF6_DFSDM1;
  HAL_GPIO_Init(DF_CKOUT_GPIO_Port, &GPIO_InitStruct);

  /*Configure GPIO pin : PA5 */
  GPIO_InitStruct.Pin = GPIO_PIN_5;
  GPIO_InitStruct.Mode = GPIO_MODE_INPUT;
  GPIO_InitStruct.Pull = GPIO_NOPULL;
  HAL_GPIO_Init(GPIOA, &GPIO_InitStruct);

  /*Configure GPIO pin : SPI2_CS_Pin */
  GPIO_InitStruct.Pin = SPI2_CS_Pin;
  GPIO_InitStruct.Mode = GPIO_MODE_OUTPUT_PP;
  GPIO_InitStruct.Pull = GPIO_NOPULL;
  GPIO_InitStruct.Speed = GPIO_SPEED_FREQ_LOW;
  HAL_GPIO_Init(SPI2_CS_GPIO_Port, &GPIO_InitStruct);

  /*Configure GPIO pins : SPI_MOSI_Pin SPI2_MISO_Pin SPI2_CLK_Pin */
  GPIO_InitStruct.Pin = SPI_MOSI_Pin|SPI2_MISO_Pin|SPI2_CLK_Pin;
  GPIO_InitStruct.Mode = GPIO_MODE_AF_PP;
  GPIO_InitStruct.Pull = GPIO_NOPULL;
  GPIO_InitStruct.Speed = GPIO_SPEED_FREQ_VERY_HIGH;
  GPIO_InitStruct.Alternate = GPIO_AF5_SPI2;
  HAL_GPIO_Init(GPIOB, &GPIO_InitStruct);

  /*Configure GPIO pin : USART2_RX_Pin */
  GPIO_InitStruct.Pin = USART2_RX_Pin;
  GPIO_InitStruct.Mode = GPIO_MODE_AF_PP;
  GPIO_InitStruct.Pull = GPIO_NOPULL;
  GPIO_InitStruct.Speed = GPIO_SPEED_FREQ_VERY_HIGH;
  GPIO_InitStruct.Alternate = GPIO_AF7_USART2;
  HAL_GPIO_Init(USART2_RX_GPIO_Port, &GPIO_InitStruct);

  /*Configure GPIO pin : DSI_TE_Pin */
  GPIO_InitStruct.Pin = DSI_TE_Pin;
  GPIO_InitStruct.Mode = GPIO_MODE_AF_PP;
  GPIO_InitStruct.Pull = GPIO_NOPULL;
  GPIO_InitStruct.Speed = GPIO_SPEED_FREQ_LOW;
  GPIO_InitStruct.Alternate = GPIO_AF11_DSI;
  HAL_GPIO_Init(DSI_TE_GPIO_Port, &GPIO_InitStruct);

  /*Configure GPIO pin : DCMI_HSYNC_Pin */
  GPIO_InitStruct.Pin = DCMI_HSYNC_Pin;
  GPIO_InitStruct.Mode = GPIO_MODE_AF_PP;
  GPIO_InitStruct.Pull = GPIO_NOPULL;
  GPIO_InitStruct.Speed = GPIO_SPEED_FREQ_LOW;
  GPIO_InitStruct.Alternate = GPIO_AF10_DCMI;
  HAL_GPIO_Init(DCMI_HSYNC_GPIO_Port, &GPIO_InitStruct);

  /*Configure GPIO pin : MFX_WAKEUP_Pin */
  GPIO_InitStruct.Pin = MFX_WAKEUP_Pin;
  GPIO_InitStruct.Mode = GPIO_MODE_OUTPUT_PP;
  GPIO_InitStruct.Pull = GPIO_NOPULL;
  GPIO_InitStruct.Speed = GPIO_SPEED_FREQ_LOW;
  HAL_GPIO_Init(MFX_WAKEUP_GPIO_Port, &GPIO_InitStruct);

  /*Configure GPIO pin : DFDATIN1_Pin */
  GPIO_InitStruct.Pin = DFDATIN1_Pin;
  GPIO_InitStruct.Mode = GPIO_MODE_AF_PP;
  GPIO_InitStruct.Pull = GPIO_NOPULL;
  GPIO_InitStruct.Speed = GPIO_SPEED_FREQ_LOW;
  GPIO_InitStruct.Alternate = GPIO_AF6_DFSDM1;
  HAL_GPIO_Init(DFDATIN1_GPIO_Port, &GPIO_InitStruct);

}

void StartDefaultTask(void *argument)
{
  for(;;)
  {
    osDelay(1);
  }
}

void HAL_TIM_PeriodElapsedCallback(TIM_HandleTypeDef *htim)
{
  if (htim->Instance == TIM6) {
    HAL_IncTick();
  }
}

void Error_Handler(void)
{
  __disable_irq();
  while (1)
  {
  }
}
